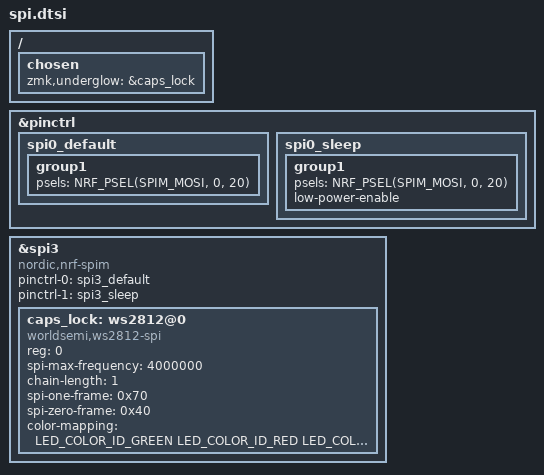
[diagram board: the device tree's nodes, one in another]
/*
 * copyright (c) 2025 ZMK project contributors
 *
 * SPDX-license-identifier: MIT
 */

 #include <dt-bindings/led/led.h>

/ {
    chosen {
        zmk,underglow = &caps_lock;
    };
};

&pinctrl {
    spi0_default: spi0_default {
        group1 {
            psels = <NRF_PSEL(SPIM_MOSI, 0, 20)>;
        };
    };

    spi0_sleep: spi0_sleep {
        group1 {
            psels = <NRF_PSEL(SPIM_MOSI, 0, 20)>;
            low-power-enable;
        };
    };
};

&spi3 {
    compatible = "nordic,nrf-spim";
    status = "okay";
    pinctrl-0 = <&spi3_default>;
    pinctrl-1 = <&spi3_sleep>;
    pinctrl-names = "default", "sleep";

    caps_lock: ws2812@0 {
        compatible = "worldsemi,ws2812-spi";

        /* SPI */
        reg = <0>; /* ignored, but necessary for SPI bindings */
        spi-max-frequency = <4000000>;

        /* WS2812 */
        chain-length = <1>; /* number of LEDs */
        spi-one-frame = <0x70>;
        spi-zero-frame = <0x40>;
        color-mapping = <LED_COLOR_ID_GREEN LED_COLOR_ID_RED LED_COLOR_ID_BLUE>;
    };
};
